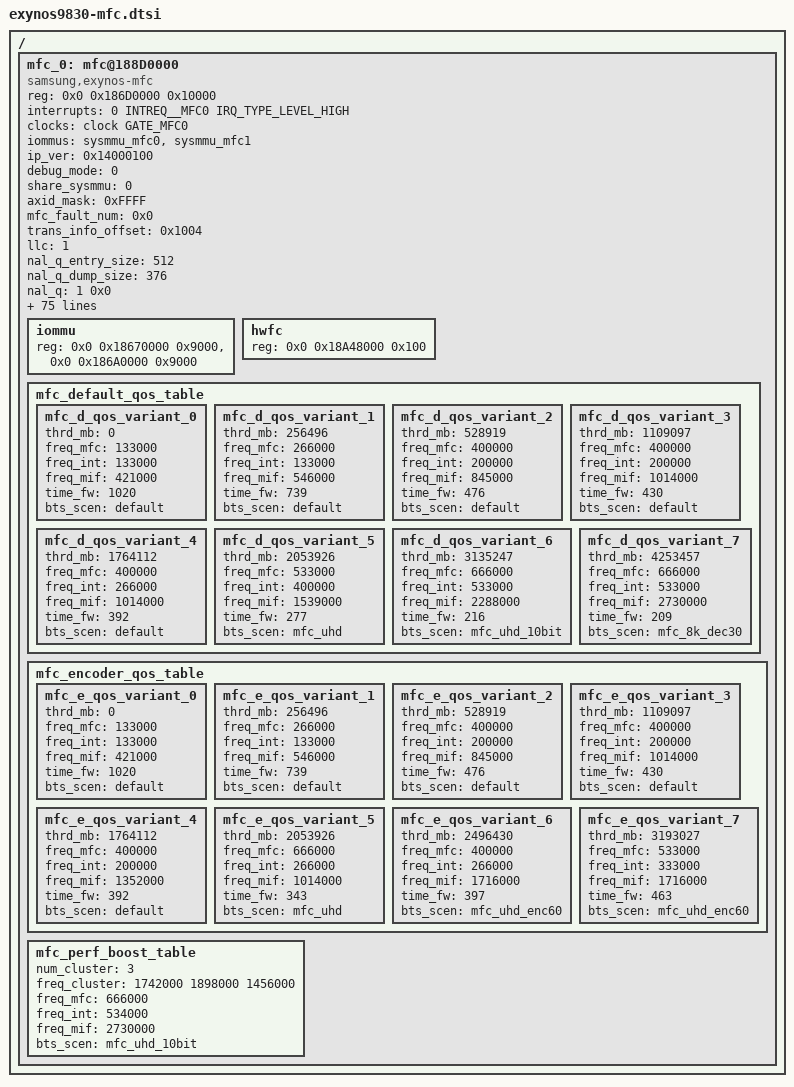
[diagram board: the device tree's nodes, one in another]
/*
 * SAMSUNG EXYNOS SoC mfc device tree source
 *
 * Copyright (c) 2018 Samsung Electronics Co., Ltd.
 *		http://www.samsung.com
 *
 * SAMSUNG EXYNOS SoC mfc device nodes are listed in this file.
 * EXYNOS based board files can include this file and provide
 * values for board specfic bindings.
 *
 * This program is free software; you can redistribute it and/or modify
 * it under the terms of the GNU General Public License version 2 as
 * published by the Free Software Foundation.
 */

#include <dt-bindings/clock/exynos9830.h>
#include <dt-bindings/interrupt-controller/exynos9830.h>

/ {
	mfc_0: mfc@188D0000 {
		/* Basic setting */
		compatible = "samsung,exynos-mfc";
		reg = <0x0 0x186D0000 0x10000>;
		interrupts = <0 INTREQ__MFC0 IRQ_TYPE_LEVEL_HIGH>;
		clock-names = "aclk_mfc";
		clocks = <&clock GATE_MFC0>;
		iommus = <&sysmmu_mfc0>, <&sysmmu_mfc1>;

		/* MFC version */
		ip_ver = <0x14000100>;

		/* Debug mode */
		debug_mode = <0>;

		/* Sysmmu check */
		share_sysmmu = <0>;
		axid_mask = <0xFFFF>;
		mfc_fault_num = <0x0>;
		trans_info_offset = <0x1004>;

		/* LLC (Last Level Cache) */
		llc = <1>;

		/* NAL-Q size */
		nal_q_entry_size = <512>;
		nal_q_dump_size = <376>;

		/* Features <on/off version> */
		nal_q = <1 0x0>;
		skype = <1 0x0>;
		black_bar = <1 0x0>;
		color_aspect_dec = <1 0x0>;
		static_info_dec = <1 0x0>;
		color_aspect_enc = <1 0x0>;
		static_info_enc = <1 0x180314>;
		hdr10_plus = <1 0x180709>;
		vp9_stride_align = <1 0x0>;
		sbwc_uncomp = <1 0x190702>;
		mem_clear = <1 0x0>;
		/* Support from v11.0 (except 11.2) */
		wait_fw_status = <1 0x190122>;
		wait_nalq_status = <1 0x191107>;
		/* DRM switch predict for cache flush */
		drm_switch_predict = <1 0x0>;
		/* Support SBWC per-frame control for encoder src */
		sbwc_enc_src_ctrl = <1 0x200110>;

		/* Default 10bit format for decoding (1: P010, 0: 8+2) */
		P010_decoding = <1>;
		/* Dithering option for 8bit display device */
		dithering_enable = <0>;

		/* Formats */
		support_10bit = <1>;
		support_422 = <1>;
		support_rgb = <1>;

		/* SBWC */
		support_sbwc = <1>;
		support_sbwcl = <0>;

		/* HDR10+ num max window */
		max_hdr_win = <1>;

		/* Encoder default parameter: max number is 100 */
		enc_param_num = <25>;
		enc_param_addr = <0xF7B4 0xF7B8 0xF7B0 0xF798 0xFA2C
				0xF790 0xFA34 0xFA38 0xFA3C 0xF7C0
				0xF7C8 0xF7CC 0xFA60 0xFDD4 0xFDDC
				0xFB54 0xFB58 0xFBA8 0xFD90 0xFD94
				0xFD40 0xFD48 0xFD4C 0xFD50 0xFD80>;
		enc_param_val = <0x80 0x80 0x0 0x4000 0x3FD00
				0x0 0x0 0x2710 0x3E8 0x0
				0x0 0x0 0x0 0x8050D211 0x0
				0x3011 0x0 0x0 0x2D 0xA00
				0x1D 0xF4240 0x33003300 0x2 0x1>;

		/* BW <peak, read, write> : KB/UHD frame */
		bw_enc_h264		= <45456 56112 11170>;
		bw_enc_hevc		= <46756 52766 9763>;
		bw_enc_hevc_10bit	= <53865 64753 12556>;
		bw_enc_vp8		= <64000 67318 22518>;
		bw_enc_vp9		= <72326 59726 16530>;
		bw_enc_vp9_10bit	= <149085 114928 31419>;
		bw_enc_mpeg4		= <44647 55324 9531>;
		bw_dec_h264		= <32605 34381 21263>;
		bw_dec_hevc		= <29973 28851 17538>;
		bw_dec_hevc_10bit	= <52859 46245 31351>;
		bw_dec_vp8		= <28672 30468 22324>;
		bw_dec_vp9		= <18351 18947 16877>;
		bw_dec_vp9_10bit	= <42384 34452 31766>;
		bw_dec_mpeg4		= <31540 25368 15770>;

		/* BW <peak, read, write> : KB/UHD frame. For SBWC format */
		/* It is valid when only support_sbwc = <1> */
		sbwc_bw_enc_h264	= <31622 32183 7065>;
		sbwc_bw_enc_hevc	= <24044 27526 5888>;
		sbwc_bw_enc_hevc_10bit	= <32666 37594 8841>;
		sbwc_bw_enc_vp8		= <32666 37594 8841>;
		sbwc_bw_enc_vp9		= <23276 26884 8702>;
		sbwc_bw_enc_vp9_10bit	= <42302 41116 14052>;
		sbwc_bw_enc_mpeg4	= <32666 37594 8841>;
		sbwc_bw_dec_h264	= <23757 18603 13620>;
		sbwc_bw_dec_hevc	= <15309 15387 10279>;
		sbwc_bw_dec_hevc_10bit	= <20808 20602 14868>;
		sbwc_bw_dec_vp8		= <17203 18281 13394>;
		sbwc_bw_dec_vp9		= <11121 9691 8999>;
		sbwc_bw_dec_vp9_10bit	= <17787 15582 14413>;
		sbwc_bw_dec_mpeg4	= <18924 15221 9462>;

		/* QoS */
		num_default_qos_steps = <8>;
		num_encoder_qos_steps = <8>;
		max_mb = <5315425>;
		mfc_freq_control = <1>;
		mo_control = <1>;
		bw_control = <1>;
		num_mfc_freq = <5>;
		mfc_freqs = <133000 266000 400000 533000 666000>;
		/* spec: H264(240M) VP8(80M) */
		max_Kbps = <245760 81920>;

		/* QoS weight (%) */
		qos_weight_h264_hevc = <100>;
		qos_weight_vp8_vp9 = <100>;
		qos_weight_other_codec = <25>;
		qos_weight_3plane = <80>;
		qos_weight_10bit = <75>;
		qos_weight_422 = <70>;
		qos_weight_bframe = <50>;
		qos_weight_num_of_ref = <60>;
		qos_weight_gpb = <50>;
		qos_weight_num_of_tile = <75>;
		qos_weight_super64_bframe = <60>;

		/* Sub nodes for sysmmu, hwfc and mmcache */
		#address-cells = <2>;
		#size-cells = <1>;
		ranges;
		iommu {
			reg = <0x0 0x18670000 0x9000>,
			    <0x0 0x186A0000 0x9000>;
		};
		hwfc {
			reg = <0x0 0x18A48000 0x100>;
		};

		/* Default QoS table */
		mfc_default_qos_table {
			mfc_d_qos_variant_0 {
				thrd_mb = <0>;
				freq_mfc = <133000>;
				freq_int = <133000>;
				freq_mif = <421000>;
				time_fw = <1020>;
				bts_scen = "default";
			};
			mfc_d_qos_variant_1 {
				thrd_mb = <256496>;
				freq_mfc = <266000>;
				freq_int = <133000>;
				freq_mif = <546000>;
				time_fw = <739>;
				bts_scen = "default";
			};
			mfc_d_qos_variant_2 {
				thrd_mb = <528919>;
				freq_mfc = <400000>;
				freq_int = <200000>;
				freq_mif = <845000>;
				time_fw = <476>;
				bts_scen = "default";
			};
			mfc_d_qos_variant_3 {
				thrd_mb = <1109097>;
				freq_mfc = <400000>;
				freq_int = <200000>;
				freq_mif = <1014000>;
				time_fw = <430>;
				bts_scen = "default";
			};
			mfc_d_qos_variant_4 {
				thrd_mb = <1764112>;
				freq_mfc = <400000>;
				freq_int = <266000>;
				freq_mif = <1014000>;
				time_fw = <392>;
				bts_scen = "default";
			};
			mfc_d_qos_variant_5 {
				thrd_mb = <2053926>;
				freq_mfc = <533000>;
				freq_int = <400000>;
				freq_mif = <1539000>;
				time_fw = <277>;
				bts_scen = "mfc_uhd";
			};
			mfc_d_qos_variant_6 {
				thrd_mb = <3135247>;
				freq_mfc = <666000>;
				freq_int = <533000>;
				freq_mif = <2288000>;
				time_fw = <216>;
				bts_scen = "mfc_uhd_10bit";
			};
			mfc_d_qos_variant_7 {
				thrd_mb = <4253457>;
				freq_mfc = <666000>;
				freq_int = <533000>;
				freq_mif = <2730000>;
				time_fw = <209>;
				bts_scen = "mfc_8k_dec30";
			};
		};

		/* Encoder only QoS table */
		mfc_encoder_qos_table {
			mfc_e_qos_variant_0 {
				thrd_mb = <0>;
				freq_mfc = <133000>;
				freq_int = <133000>;
				freq_mif = <421000>;
				time_fw = <1020>;
				bts_scen = "default";
			};
			mfc_e_qos_variant_1 {
				thrd_mb = <256496>;
				freq_mfc = <266000>;
				freq_int = <133000>;
				freq_mif = <546000>;
				time_fw = <739>;
				bts_scen = "default";
			};
			mfc_e_qos_variant_2 {
				thrd_mb = <528919>;
				freq_mfc = <400000>;
				freq_int = <200000>;
				freq_mif = <845000>;
				time_fw = <476>;
				bts_scen = "default";
			};
			mfc_e_qos_variant_3 {
				thrd_mb = <1109097>;
				freq_mfc = <400000>;
				freq_int = <200000>;
				freq_mif = <1014000>;
				time_fw = <430>;
				bts_scen = "default";
			};
			mfc_e_qos_variant_4 {
				thrd_mb = <1764112>;
				freq_mfc = <400000>;
				freq_int = <200000>;
				freq_mif = <1352000>;
				time_fw = <392>;
				bts_scen = "default";
			};
			mfc_e_qos_variant_5 {
				thrd_mb = <2053926>;
				freq_mfc = <666000>;
				freq_int = <266000>;
				freq_mif = <1014000>;
				time_fw = <343>;
				bts_scen = "mfc_uhd";
			};
			mfc_e_qos_variant_6 {
				thrd_mb = <2496430>;
				freq_mfc = <400000>;
				freq_int = <266000>;
				freq_mif = <1716000>;
				time_fw = <397>;
				bts_scen = "mfc_uhd_enc60";
			};
			mfc_e_qos_variant_7 {
				thrd_mb = <3193027>;
				freq_mfc = <533000>;
				freq_int = <333000>;
				freq_mif = <1716000>;
				time_fw = <463>;
				bts_scen = "mfc_uhd_enc60";
			};
		};

		/* QoS table for performance boost mode */
		mfc_perf_boost_table {
			num_cluster = <3>;
			freq_cluster = <1742000 1898000 1456000>;
			freq_mfc = <666000>;
			freq_int = <534000>;
			freq_mif = <2730000>;
			bts_scen = "mfc_uhd_10bit";
		};
	};
};
